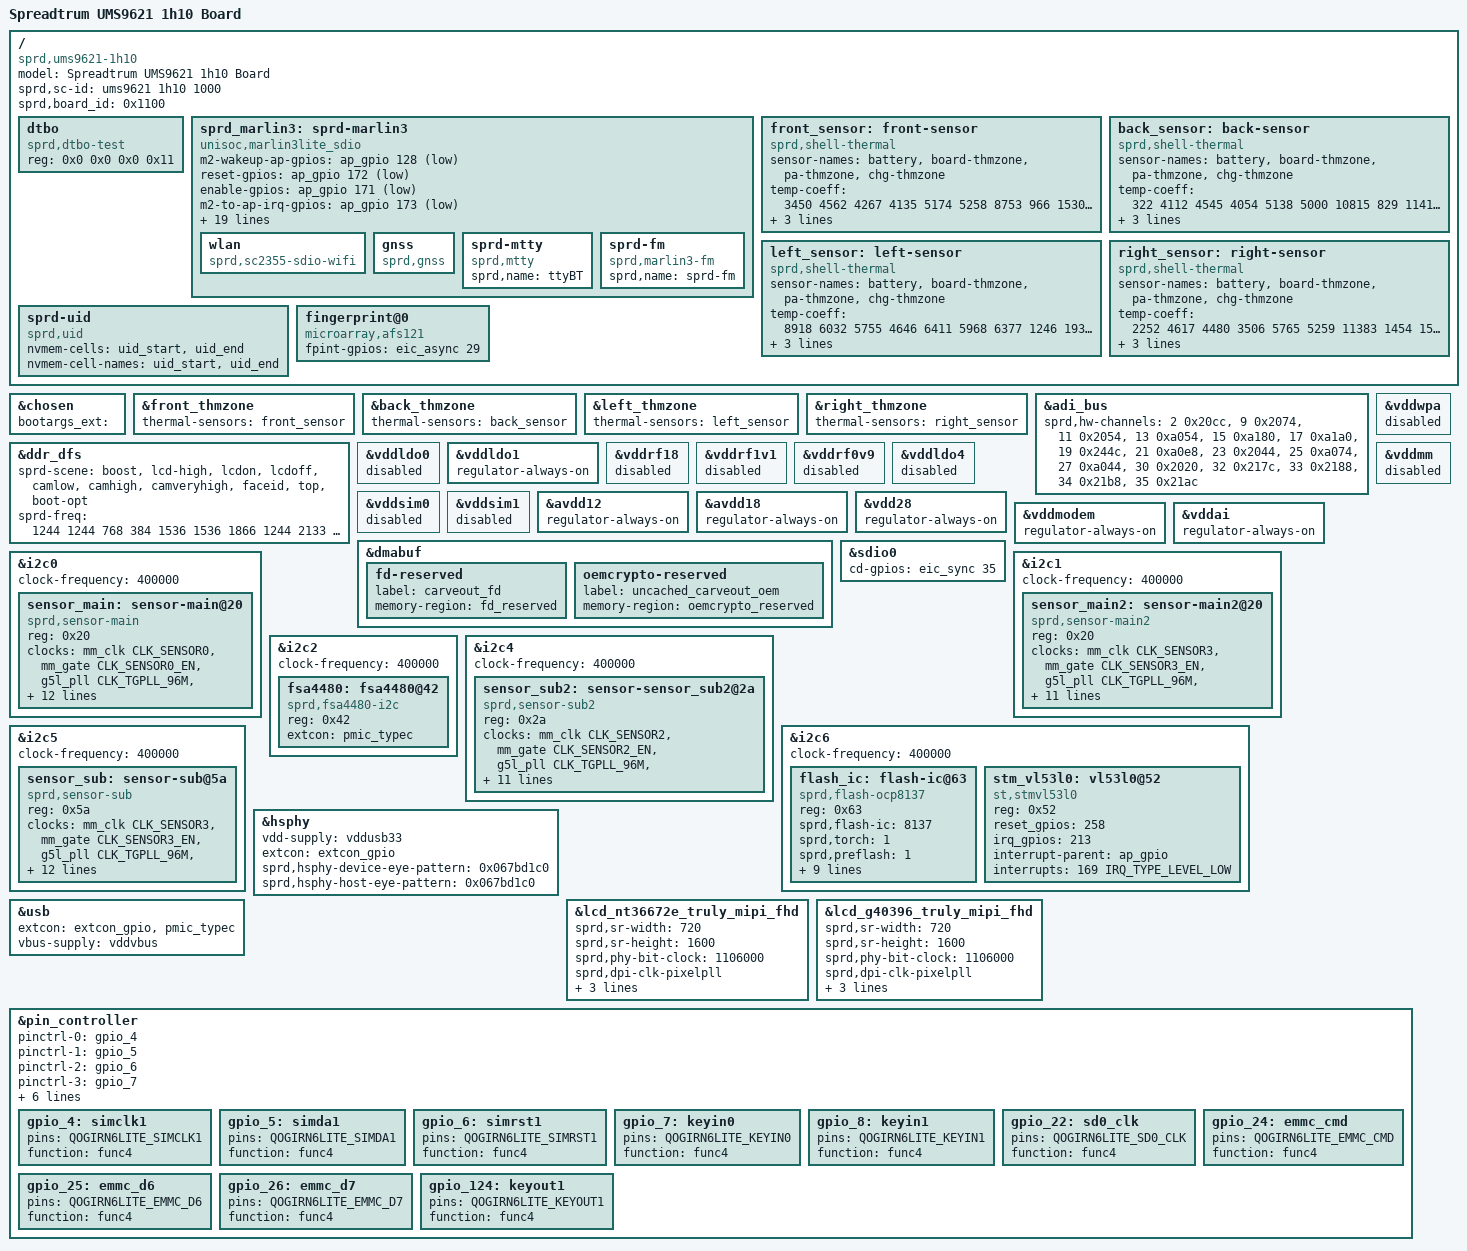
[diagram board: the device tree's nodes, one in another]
/dts-v1/;
/plugin/;
#include <dt-bindings/gpio/gpio.h>
#include <dt-bindings/interrupt-controller/arm-gic.h>
#include <dt-bindings/clock/sprd,ums9621-clk.h>
#include <dt-bindings/usb/pd.h>
#include "lcd/lcd_g40396_truly_mipi_fhd.dtsi"
#include "lcd/lcd_nt36672e_truly_mipi_fhd.dtsi"
#include "lcd/lcd_dummy_mipi.dtsi"
#include "reserved-memory/ums9621-1h10-overlay.dtsi"
#include "touchscreen/ums9621-spi1-gpio13-14-tp.dtsi"
#include "battery/ums9621-1h10-overlay.dtsi"
#include <dt-bindings/mfd/sprd,ump9620-regs.h>
#include <dt-bindings/mfd/sprd,ump9620-mask.h>
#include <dt-bindings/input/input.h>
#include "wcn/wcn-marlin3lite-umw2652-register.dtsi"

/ {

	model = "Spreadtrum UMS9621 1h10 Board";

	compatible = "sprd,ums9621-1h10";

	sprd,sc-id = "ums9621 1h10 1000";

	sprd,board_id = <0x1100>;

	fragment {
		target-path = "/";
		__overlay__ {
			#address-cells = <2>;
			#size-cells = <2>;

			dtbo: dtbo {
				compatible = "sprd,dtbo-test";
				reg = <0x0 0x0 0x0 0x11>;
			};
			sprd_marlin3: sprd-marlin3 {
				compatible = "unisoc,marlin3lite_sdio";
				m2-wakeup-ap-gpios = <&ap_gpio 128 GPIO_ACTIVE_LOW>;
				reset-gpios = <&ap_gpio 172 GPIO_ACTIVE_LOW>;
				enable-gpios = <&ap_gpio 171 GPIO_ACTIVE_LOW>;
				m2-to-ap-irq-gpios = <&ap_gpio 173 GPIO_ACTIVE_LOW>;
				/* xtal-26m-clk-type = "TCXO"; */
				avdd12-supply = <&vddwcn>;
				avdd33-supply = <&vddwifipa>;
				dcxo18-supply = <&vddsim2>;
				clock-names = "clk_32k","source","enable";
				clocks = <&aonapb_gate CLK_AUX0>,
					 <&ext_32k>,
					 <&aonapb_gate CLK_AUX0_EB>;
				extcon = <&sdio1>;
				sdhci-name = <&sdio1>;
				sprd,check-emmc-ufs = "need_to_check_emmc_or_ufs";
				sprd,btwf-file-name = "/dev/block/by-name/wcnmodem";
				sprd,gnss-file-name = "/vendor/firmware/gnssmodem.bin";
				adma-tx;
				adma-rx;
				btwf-wakeup-lock;
				/*
				 * bound parameter:
				 * [0]:addr offset, [1]:mask, [2]:unboundval, [3]:boundval
				 */
				avdd12-bound-wbreq = <REG_ANA_LDO_XTL_EN10 MASK_ANA_LDO_VDDWCN_EXT_XTL3_EN 0x0 MASK_ANA_LDO_VDDWCN_EXT_XTL3_EN>;
				avdd33-bound-wbreq = <REG_ANA_LDO_XTL_EN11 MASK_ANA_LDO_VDDWIFIPA_EXT_XTL3_EN 0x0 MASK_ANA_LDO_VDDWIFIPA_EXT_XTL3_EN>;

				wlan {
					compatible = "sprd,sc2355-sdio-wifi";
				};

				gnss {
					compatible = "sprd,gnss";
				};

				sprd-mtty {
					compatible = "sprd,mtty";
					sprd,name = "ttyBT";
				};

				sprd-fm {
					compatible = "sprd,marlin3-fm";
					sprd,name = "sprd-fm";
				};

			};

			front_sensor: front-sensor {
				compatible = "sprd,shell-thermal";
				#thermal-sensor-cells = <0>;
				sensor-names = "battery",
						"board-thmzone",
						"pa-thmzone",
						"chg-thmzone";
				temp-coeff = <3450 4562 4267 4135 5174 5258 8753
						966 1530 3008 3021 2380 1894 745
						6010 6332 5300 4423 4532 5950 10206
						1916 5326 4557 4932 5549 3245 4574>;
				coeff-offset = <4000>;
				temp-const = <630>;
				const-offset = <2000>;
			};

			back_sensor: back-sensor {
				compatible = "sprd,shell-thermal";
				#thermal-sensor-cells = <0>;
				sensor-names = "battery",
						"board-thmzone",
						"pa-thmzone",
						"chg-thmzone";
				temp-coeff = <322 4112 4545 4054 5138 5000 10815
						829 1141 2558 2645 1886 1441 380
						5899 6526 5713 4828 4838 6388 11096
						1852 5631 4901 5224 5799 3497 4939>;
				coeff-offset = <4000>;
				temp-const = <515>;
				const-offset = <2000>;
			};

			left_sensor: left-sensor {
				compatible = "sprd,shell-thermal";
				#thermal-sensor-cells = <0>;
				sensor-names = "battery",
						"board-thmzone",
						"pa-thmzone",
						"chg-thmzone";
				temp-coeff = <8918 6032 5755 4646 6411 5968 6377
						1246 1937 3439 3614 2973 2568 699
						5088 7642 6623 6152 5712 7170 11906
						3498 6971 5889 5866 7108 3965 5822>;
				coeff-offset = <5000>;
				temp-const = <25>;
				const-offset = <2000>;
			};

			right_sensor: right-sensor {
				compatible = "sprd,shell-thermal";
				#thermal-sensor-cells = <0>;
				sensor-names = "battery",
						"board-thmzone",
						"pa-thmzone",
						"chg-thmzone";
				temp-coeff = <2252 4617 4480 3506 5765 5259 11383
						1454 1525 3074 2972 2298 1904 243
						3768 6359 5443 4526 4526 6126 10859
						1284 5224 4694 5196 5660 3136 4466>;
				coeff-offset = <4000>;
				temp-const = <364>;
				const-offset = <2000>;
			};

			sprd-uid {
				compatible = "sprd,uid";
				nvmem-cells = <&uid_start>, <&uid_end>;
				nvmem-cell-names = "uid_start", "uid_end";
			};

			fingerprint@0 {
				compatible = "microarray,afs121";
				fpint-gpios = <&eic_async 29 0>;
			};


		};
	};
};

&chosen {
	bootargs_ext = "";
};

&front_thmzone {
	status = "okay";
	thermal-sensors = <&front_sensor>;
};

&back_thmzone {
	status = "okay";
	thermal-sensors = <&back_sensor>;
};

&left_thmzone {
	status = "okay";
	thermal-sensors = <&left_sensor>;
};

&right_thmzone {
	status = "okay";
	thermal-sensors = <&right_sensor>;
};

&adi_bus {
	sprd,hw-channels = <2 0x20cc>, <9 0x2074>, <11 0x2054>, <13 0xa054>,
			<15 0xa180>, <17 0xa1a0>, <19 0x244c>, <21 0xa0e8>,
			<23 0x2044>, <25 0xa074>, <27 0xa044>, <30 0x2020>,
			<32 0x217c>, <33 0x2188>, <34 0x21b8>, <35 0x21ac>;
};

&ddr_dfs {
		sprd-scene = "boost", "lcd-high", "lcdon", "lcdoff", "camlow",
			"camhigh", "camveryhigh", "faceid", "top", "boot-opt";
		sprd-freq = <1244 1244 768 384 1536 1536 1866 1244 2133 1866>;
};

&vddwpa {
	status = "disabled";
};

&vddldo0 {
	status = "disabled";
};

&vddldo1 {
	regulator-always-on;
};

&vddrf18 {
	status = "disabled";
};

&vddrf1v1 {
	status = "disabled";
};

&vddrf0v9 {
	status = "disabled";
};

&vddldo4 {
	status = "disabled";
};

&vddmm {
	status = "disabled";
};

&vddsim0 {
	status = "disabled";
};

&vddsim1 {
	status = "disabled";
};

&avdd12 {
	regulator-always-on;
};

&avdd18 {
	regulator-always-on;
};

&vdd28 {
	regulator-always-on;
};

&vddmodem {
	regulator-always-on;
};

&vddai {
	regulator-always-on;
};

&dmabuf {

	fd-reserved {
		label = "carveout_fd";
		memory-region = <&fd_reserved>;
	};
	oemcrypto-reserved {
		label = "uncached_carveout_oem";
		memory-region = <&oemcrypto_reserved>;
	};
};

&sdio0 {
	cd-gpios = <&eic_sync 35 GPIO_ACTIVE_HIGH>;
};

&i2c0 {
	status = "okay";
	clock-frequency = <400000>;

	sensor_main: sensor-main@20 {
		compatible = "sprd,sensor-main";
		reg = <0x20>;
		clock-names = "clk_src","sensor_eb",
			"clk_96m","clk_64m",
			"clk_51m2","clk_48m","clk_26m";
		clocks = <&mm_clk CLK_SENSOR0>,<&mm_gate CLK_SENSOR0_EN>,
				<&g5l_pll CLK_TGPLL_96M>,<&g5l_pll CLK_TGPLL_64M>,
				<&g5l_pll CLK_TGPLL_51M2>,<&g5l_pll CLK_TGPLL_48M>,<&ext_26m>;
		vddio-supply = <&vddcamio>;
		vddcama-supply = <&vddcama0>;
		vddcamd-supply = <&vddcamd0>;
		vddcammot-supply = <&vddcammot0>;
		reset-gpios = <&ap_gpio 39 0>;
		power-down-gpios = <&ap_gpio 45 0>;
		sprd,phyid = <0>;
		csi = <&csi0>;
		power-domains = <&mm_domain>;
	};


};

&i2c1 {
	status = "okay";
	clock-frequency = <400000>;

	sensor_main2: sensor-main2@20 {
		compatible = "sprd,sensor-main2";
		reg = <0x20>;
		clock-names = "clk_src","sensor_eb",
			"clk_96m","clk_64m",
			"clk_51m2","clk_48m","clk_26m";
		clocks = <&mm_clk CLK_SENSOR3>,<&mm_gate CLK_SENSOR3_EN>,
			<&g5l_pll CLK_TGPLL_96M>,<&g5l_pll CLK_TGPLL_64M>,
			<&g5l_pll CLK_TGPLL_51M2>,<&g5l_pll CLK_TGPLL_48M>,<&ext_26m>;
		vddio-supply = <&vddcamio>;
		vddcama-supply = <&vddcama1>;
		/*avdd-gpios = <&ap_gpio 79 0>;*/
		vddcamd-supply = <&vddcamd1>;
		reset-gpios = <&ap_gpio 40 0>;
		power-down-gpios = <&ap_gpio 46 0>;
		sprd,phyid = <5>;/*2 for 2p2*/
		csi = <&csi2>;
		power-domains = <&mm_domain>;
	};
};

&i2c2 {
	status = "okay";
	clock-frequency = <400000>;

	fsa4480: fsa4480@42 {
		compatible = "sprd,fsa4480-i2c";
		reg = <0x42>;
		extcon = <&pmic_typec>;
	};
};

&i2c4 {
	status = "okay";
	clock-frequency = <400000>;

	sensor_sub2: sensor-sensor_sub2@2a {
		compatible = "sprd,sensor-sub2";
		reg = <0x2a>;
		clock-names = "clk_src","sensor_eb",
			"clk_96m","clk_64m",
			"clk_51m2","clk_48m","clk_26m";
		clocks = <&mm_clk CLK_SENSOR2>,<&mm_gate CLK_SENSOR2_EN>,
			<&g5l_pll CLK_TGPLL_96M>,<&g5l_pll CLK_TGPLL_64M>,
			<&g5l_pll CLK_TGPLL_51M2>,<&g5l_pll CLK_TGPLL_48M>,<&ext_26m>;
		vddio-supply = <&vddcamio>;
		vddcama-supply = <&vddcama2>;
		vddcamd-supply = <&vddcamd2>;
		vddcammot-supply = <&vddcammot1>;
		reset-gpios = <&ap_gpio 41 0>;
		/*power-down-gpios = <&ap_gpio 50 0>;*/
		sprd,phyid = <6>;
		csi = <&csi2>;
		power-domains = <&mm_domain>;
	};

};

&i2c5 {
	status = "okay";
	clock-frequency = <400000>;

	sensor_sub: sensor-sub@5a {
		compatible = "sprd,sensor-sub";
		reg = <0x5a>;
		clock-names = "clk_src","sensor_eb",
			"clk_96m","clk_64m",
			"clk_51m2","clk_48m","clk_26m";
		clocks = <&mm_clk CLK_SENSOR3>,<&mm_gate CLK_SENSOR3_EN>,
			<&g5l_pll CLK_TGPLL_96M>,<&g5l_pll CLK_TGPLL_64M>,
			<&g5l_pll CLK_TGPLL_51M2>,<&g5l_pll CLK_TGPLL_48M>,<&ext_26m>;
		vddio-supply = <&vddcamio>;
		vddcama-supply = <&vddcama0>;
		vddcamd-supply = <&vddcamd0>;
		vddcammot-supply = <&vddcammot0>;
		reset-gpios = <&ap_gpio 42 0>;
		power-down-gpios = <&ap_gpio 48 0>;
		sprd,phyid = <1>;
		csi = <&csi1>;
		power-domains = <&mm_domain>;
	};


};

&i2c6 {
	status = "okay";
	clock-frequency = <400000>;

	flash_ic: flash-ic@63 {
		compatible = "sprd,flash-ocp8137";
		reg = <0x63>;
		sprd,flash-ic = <8137>;
		sprd,torch = <1>;
		sprd,preflash = <1>;
		sprd,highlight = <1>;
		sprd,torch-level = <128>;
		sprd,preflash-level = <128>;
		sprd,highlight-level = <128>;
		sprd,lvfm-enable = <1>;
		flash-torch-en-gpios = <&ap_gpio 112 0>;
		flash-chip-en-gpios = <&ap_gpio 119 0>;
		flash-en-gpios = <&ap_gpio 111 0>;
		flash-sync-gpios = <&ap_gpio 59 0>;
	};

	stm_vl53l0: vl53l0@52 {
		compatible = "st,stmvl53l0";
		reg = <0x52>;
		reset_gpios = <258>;
		irq_gpios = <213>;
		interrupt-parent = <&ap_gpio>;
		interrupts = <169 IRQ_TYPE_LEVEL_LOW>;
	};
};

&hsphy {
	vdd-supply = <&vddusb33>;
	extcon = <&extcon_gpio>;
	sprd,hsphy-device-eye-pattern = <0x067bd1c0>;
	sprd,hsphy-host-eye-pattern = <0x067bd1c0>;
	status = "okay";
};

&usb {
	extcon = <&extcon_gpio>, <&pmic_typec>;
	vbus-supply = <&vddvbus>;
	status = "okay";
};

&lcd_nt36672e_truly_mipi_fhd {
	sprd,sr-width = <720>;
	sprd,sr-height = <1600>;

	sprd,phy-bit-clock = <1106000>;
	sprd,dpi-clk-pixelpll;
	sprd,dpi-clk-div = <0>;
	sprd,video-lp-cmd-enable = <0>;
	sprd,hporch-lp-disable = <0>;
};

&lcd_g40396_truly_mipi_fhd {
	sprd,sr-width = <720>;
	sprd,sr-height = <1600>;

	sprd,phy-bit-clock = <1106000>;
	sprd,dpi-clk-pixelpll;
	sprd,dpi-clk-div = <0>;
	sprd,video-lp-cmd-enable = <0>;
	sprd,hporch-lp-disable = <0>;
};

&pin_controller {
	pinctrl-names =
	/* IM1_CLK ,SIM1_DA ,SIM1_RST ,keyin0 */
	 "gpio_4", "gpio_5", "gpio_6", "gpio_7",
	/* keyin1 ,sd0_clk, emmc_cmd */
	"gpio_8", "gpio_22", "gpio_24",
	/* emmc_d6, emmc_d7, emmc_d7 */
	"gpio_25", "gpio_26", "gpio_124";

	pinctrl-0 = <&gpio_4>;
	pinctrl-1 = <&gpio_5>;
	pinctrl-2 = <&gpio_6>;
	pinctrl-3 = <&gpio_7>;
	pinctrl-4 = <&gpio_8>;
	pinctrl-5 = <&gpio_22>;
	pinctrl-6 = <&gpio_24>;
	pinctrl-7 = <&gpio_25>;
	pinctrl-8 = <&gpio_26>;
	pinctrl-9 = <&gpio_124>;

	gpio_4: simclk1 {
		pins = "QOGIRN6LITE_SIMCLK1";
		function = "func4";
	};

	gpio_5: simda1 {
		pins = "QOGIRN6LITE_SIMDA1";
		function = "func4";
	};

	gpio_6: simrst1 {
		pins = "QOGIRN6LITE_SIMRST1";
		function = "func4";
	};

	gpio_7: keyin0 {
		pins = "QOGIRN6LITE_KEYIN0";
		function = "func4";
	};

	gpio_8: keyin1 {
		pins = "QOGIRN6LITE_KEYIN1";
		function = "func4";
	};

	gpio_22: sd0_clk {
		pins = "QOGIRN6LITE_SD0_CLK";
		function = "func4";
	};

	gpio_24: emmc_cmd {
		pins = "QOGIRN6LITE_EMMC_CMD";
		function = "func4";
	};

	gpio_25: emmc_d6 {
		pins = "QOGIRN6LITE_EMMC_D6";
		function = "func4";
	};

	gpio_26: emmc_d7 {
		pins = "QOGIRN6LITE_EMMC_D7";
		function = "func4";
	};

	gpio_124: keyout1 {
		pins = "QOGIRN6LITE_KEYOUT1";
		function = "func4";
	};
};
